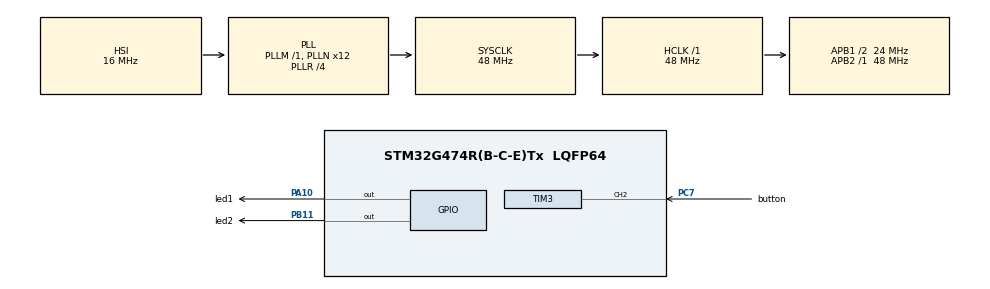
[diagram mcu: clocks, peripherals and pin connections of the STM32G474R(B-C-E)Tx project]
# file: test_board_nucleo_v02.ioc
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Mcu.Family=STM32G4
Mcu.Name=STM32G474R(B-C-E)Tx
Mcu.Package=LQFP64
NVIC.PriorityGroup=NVIC_PRIORITYGROUP_4
NVIC.TIM1_UP_TIM16_IRQn=true\:0\:0\:false\:false\:true\:true\:true\:true
NVIC.TIM3_IRQn=true\:0\:0\:false\:false\:true\:true\:true\:true
PA10.GPIO_Label=led1
PA10.Signal=GPIO_Output
PA13.Mode=Serial_Wire
PA13.Signal=SYS_JTMS-SWDIO
PA14.Mode=Serial_Wire
PA14.Signal=SYS_JTCK-SWCLK
PB11.GPIO_Label=led2
PB11.Signal=GPIO_Output
PC7.GPIO_Label=button
PC7.Signal=S_TIM3_CH2
PF0-OSC_IN.Mode=HSE-External-Oscillator
PF0-OSC_IN.Signal=RCC_OSC_IN
PF1-OSC_OUT.Mode=HSE-External-Oscillator
PF1-OSC_OUT.Signal=RCC_OSC_OUT
ProjectManager.HeapSize=0x200
ProjectManager.StackSize=0x400
ProjectManager.TargetToolchain=MDK-ARM V5.27
RCC.ADC12Freq_Value=48000000
RCC.ADC345Freq_Value=48000000
RCC.AHBFreq_Value=48000000
RCC.APB1CLKDivider=RCC_HCLK_DIV2
RCC.APB1Freq_Value=24000000
RCC.APB1TimFreq_Value=48000000
RCC.APB2Freq_Value=48000000
RCC.APB2TimFreq_Value=48000000
RCC.CortexFreq_Value=48000000
RCC.EXTERNAL_CLOCK_VALUE=12288000
RCC.HCLKFreq_Value=48000000
RCC.HSE_VALUE=8000000
RCC.HSI48_VALUE=48000000
RCC.HSI_VALUE=16000000
RCC.LSE_VALUE=32768
RCC.PLLN=12
RCC.PLLR=RCC_PLLR_DIV4
RCC.SYSCLKFreq_VALUE=48000000
RCC.SYSCLKSource=RCC_SYSCLKSOURCE_PLLCLK
RCC.USBFreq_Value=96000000
RCC.VCOOutputFreq_Value=192000000
SH.S_TIM3_CH2.0=TIM3_CH2,Input_Capture2_from_TI2
TIM16.Prescaler=4199
TIM3.Channel-Input_Capture1_from_TI2_63=TIM_CHANNEL_1
TIM3.Channel-Input_Capture2_from_TI2=TIM_CHANNEL_2
VP_SYS_VS_DBSignals.Mode=DisableDeadBatterySignals
VP_TIM16_VS_ClockSourceINT.Mode=Enable_Timer
VP_TIM3_VS_ClockSourceINT.Mode=Internal
VP_TIM3_VS_indirect_ch2.Mode=Input_Capture1_from_TI2_63
board=custom

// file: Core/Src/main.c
/* USER CODE BEGIN Header */
/**
  ******************************************************************************
  * @file           : main.c
  * @brief          : Main program body
  ******************************************************************************
  * @attention
  *
  * Copyright (c) 2024 STMicroelectronics.
  * All rights reserved.
  *
  * This software is licensed under terms that can be found in the LICENSE file
  * in the root directory of this software component.
  * If no LICENSE file comes with this software, it is provided AS-IS.
  *
  ******************************************************************************
  */
/* USER CODE END Header */
#include "main.h"

/* USER CODE BEGIN PTD */
#define LED_INTERVAL 1000  //to help you with the stability press button
/* USER CODE END PTD */

TIM_HandleTypeDef htim3;
TIM_HandleTypeDef htim16;

void SystemClock_Config(void);
static void MX_GPIO_Init(void);
static void MX_TIM3_Init(void);
static void MX_TIM16_Init(void);

uint16_t led_time = 0;

int main(void)
{

  /* MCU Configuration--------------------------------------------------------*/

  /* Reset of all peripherals, Initializes the Flash interface and the Systick. */
  HAL_Init();

  /* Configure the system clock */
  SystemClock_Config();

  /* Initialize all configured peripherals */
  MX_GPIO_Init();
  MX_TIM3_Init();
  MX_TIM16_Init();
  /* USER CODE BEGIN 2 */

	HAL_TIM_Base_Start_IT(&htim3); //activate the peripheral
	HAL_TIM_IC_Start_IT (&htim3, TIM_CHANNEL_1); //active the channel1
  HAL_TIM_IC_Start_IT (&htim3, TIM_CHANNEL_2); //active the channel2

	//now the interrupt is ready (button)

	HAL_TIM_Base_Start(&htim16); //start timer

  /* USER CODE END 2 */

  /* Infinite loop */
  /* USER CODE BEGIN WHILE */

	led_time = __HAL_TIM_GET_COUNTER(&htim16); //for reference to have a led blink time
	uint16_t timer_val = __HAL_TIM_GET_COUNTER(&htim16); //for reference take a basetime for interrupt press button control
  while (1)
  {
    if(__HAL_TIM_GET_COUNTER(&htim16) == (uint16_t)(timer_val + 5000)){
			HAL_GPIO_TogglePin(led1_GPIO_Port,led1_Pin);
			timer_val = __HAL_TIM_GET_COUNTER(&htim16); //update basetime
    }
  }
	/* USER CODE END 3 */
}
void HAL_TIM_IC_CaptureCallback(TIM_HandleTypeDef*htim){
	if((htim->Instance == TIM3) && ((__HAL_TIM_GetCounter(&htim16)-led_time)> LED_INTERVAL)){
		HAL_GPIO_TogglePin(led2_GPIO_Port, led2_Pin);
		led_time = __HAL_TIM_GET_COUNTER(&htim16);   //update basetime
	}
}
void SystemClock_Config(void)
{
  RCC_OscInitTypeDef RCC_OscInitStruct = {0};
  RCC_ClkInitTypeDef RCC_ClkInitStruct = {0};

  /** Configure the main internal regulator output voltage
  */
  HAL_PWREx_ControlVoltageScaling(PWR_REGULATOR_VOLTAGE_SCALE1);

  /** Initializes the RCC Oscillators according to the specified parameters
  * in the RCC_OscInitTypeDef structure.
  */
  RCC_OscInitStruct.OscillatorType = RCC_OSCILLATORTYPE_HSI;
  RCC_OscInitStruct.HSIState = RCC_HSI_ON;
  RCC_OscInitStruct.HSICalibrationValue = RCC_HSICALIBRATION_DEFAULT;
  RCC_OscInitStruct.PLL.PLLState = RCC_PLL_ON;
  RCC_OscInitStruct.PLL.PLLSource = RCC_PLLSOURCE_HSI;
  RCC_OscInitStruct.PLL.PLLM = RCC_PLLM_DIV1;
  RCC_OscInitStruct.PLL.PLLN = 12;
  RCC_OscInitStruct.PLL.PLLP = RCC_PLLP_DIV2;
  RCC_OscInitStruct.PLL.PLLQ = RCC_PLLQ_DIV2;
  RCC_OscInitStruct.PLL.PLLR = RCC_PLLR_DIV4;
  if (HAL_RCC_OscConfig(&RCC_OscInitStruct) != HAL_OK)
  {
    Error_Handler();
  }

  /** Initializes the CPU, AHB and APB buses clocks
  */
  RCC_ClkInitStruct.ClockType = RCC_CLOCKTYPE_HCLK|RCC_CLOCKTYPE_SYSCLK
                              |RCC_CLOCKTYPE_PCLK1|RCC_CLOCKTYPE_PCLK2;
  RCC_ClkInitStruct.SYSCLKSource = RCC_SYSCLKSOURCE_PLLCLK;
  RCC_ClkInitStruct.AHBCLKDivider = RCC_SYSCLK_DIV1;
  RCC_ClkInitStruct.APB1CLKDivider = RCC_HCLK_DIV2;
  RCC_ClkInitStruct.APB2CLKDivider = RCC_HCLK_DIV1;

  if (HAL_RCC_ClockConfig(&RCC_ClkInitStruct, FLASH_LATENCY_1) != HAL_OK)
  {
    Error_Handler();
  }
}

static void MX_TIM3_Init(void)
{

  TIM_ClockConfigTypeDef sClockSourceConfig = {0};
  TIM_MasterConfigTypeDef sMasterConfig = {0};
  TIM_IC_InitTypeDef sConfigIC = {0};

  htim3.Instance = TIM3;
  htim3.Init.Prescaler = 0;
  htim3.Init.CounterMode = TIM_COUNTERMODE_UP;
  htim3.Init.Period = 65535;
  htim3.Init.ClockDivision = TIM_CLOCKDIVISION_DIV1;
  htim3.Init.AutoReloadPreload = TIM_AUTORELOAD_PRELOAD_DISABLE;
  if (HAL_TIM_Base_Init(&htim3) != HAL_OK)
  {
    Error_Handler();
  }
  sClockSourceConfig.ClockSource = TIM_CLOCKSOURCE_INTERNAL;
  if (HAL_TIM_ConfigClockSource(&htim3, &sClockSourceConfig) != HAL_OK)
  {
    Error_Handler();
  }
  if (HAL_TIM_IC_Init(&htim3) != HAL_OK)
  {
    Error_Handler();
  }
  sMasterConfig.MasterOutputTrigger = TIM_TRGO_RESET;
  sMasterConfig.MasterSlaveMode = TIM_MASTERSLAVEMODE_DISABLE;
  if (HAL_TIMEx_MasterConfigSynchronization(&htim3, &sMasterConfig) != HAL_OK)
  {
    Error_Handler();
  }
  sConfigIC.ICPolarity = TIM_INPUTCHANNELPOLARITY_RISING;
  sConfigIC.ICSelection = TIM_ICSELECTION_INDIRECTTI;
  sConfigIC.ICPrescaler = TIM_ICPSC_DIV1;
  sConfigIC.ICFilter = 0;
  if (HAL_TIM_IC_ConfigChannel(&htim3, &sConfigIC, TIM_CHANNEL_1) != HAL_OK)
  {
    Error_Handler();
  }
  sConfigIC.ICSelection = TIM_ICSELECTION_DIRECTTI;
  if (HAL_TIM_IC_ConfigChannel(&htim3, &sConfigIC, TIM_CHANNEL_2) != HAL_OK)
  {
    Error_Handler();
  }

}

static void MX_TIM16_Init(void)
{

  htim16.Instance = TIM16;
  htim16.Init.Prescaler = 4199;
  htim16.Init.CounterMode = TIM_COUNTERMODE_UP;
  htim16.Init.Period = 65535;
  htim16.Init.ClockDivision = TIM_CLOCKDIVISION_DIV1;
  htim16.Init.RepetitionCounter = 0;
  htim16.Init.AutoReloadPreload = TIM_AUTORELOAD_PRELOAD_DISABLE;
  if (HAL_TIM_Base_Init(&htim16) != HAL_OK)
  {
    Error_Handler();
  }

}

static void MX_GPIO_Init(void)
{
  GPIO_InitTypeDef GPIO_InitStruct = {0};

  /* GPIO Ports Clock Enable */
  __HAL_RCC_GPIOF_CLK_ENABLE();
  __HAL_RCC_GPIOB_CLK_ENABLE();
  __HAL_RCC_GPIOC_CLK_ENABLE();
  __HAL_RCC_GPIOA_CLK_ENABLE();

  /*Configure GPIO pin Output Level */
  HAL_GPIO_WritePin(led2_GPIO_Port, led2_Pin, GPIO_PIN_RESET);

  /*Configure GPIO pin Output Level */
  HAL_GPIO_WritePin(led1_GPIO_Port, led1_Pin, GPIO_PIN_RESET);

  /*Configure GPIO pin : led2_Pin */
  GPIO_InitStruct.Pin = led2_Pin;
  GPIO_InitStruct.Mode = GPIO_MODE_OUTPUT_PP;
  GPIO_InitStruct.Pull = GPIO_NOPULL;
  GPIO_InitStruct.Speed = GPIO_SPEED_FREQ_LOW;
  HAL_GPIO_Init(led2_GPIO_Port, &GPIO_InitStruct);

  /*Configure GPIO pin : led1_Pin */
  GPIO_InitStruct.Pin = led1_Pin;
  GPIO_InitStruct.Mode = GPIO_MODE_OUTPUT_PP;
  GPIO_InitStruct.Pull = GPIO_NOPULL;
  GPIO_InitStruct.Speed = GPIO_SPEED_FREQ_LOW;
  HAL_GPIO_Init(led1_GPIO_Port, &GPIO_InitStruct);

}

void Error_Handler(void)
{
  __disable_irq();
  while (1)
  {
  }
}
